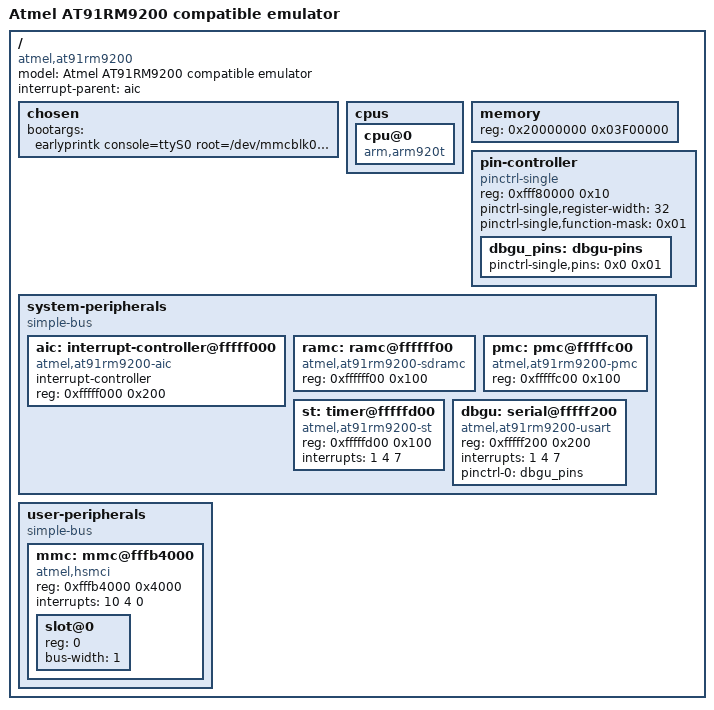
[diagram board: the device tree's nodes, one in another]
/dts-v1/;
/include/ "../ksource/arch/arm/boot/dts/skeleton.dtsi"

/ {
	
	model = "Atmel AT91RM9200 compatible emulator";
	compatible = "atmel,at91rm9200";
	interrupt-parent = <&aic>;

	chosen {
		bootargs = "earlyprintk console=ttyS0 root=/dev/mmcblk0 rootfstype=ext4 rootwait";
	};

	cpus {
		cpu@0 {
			compatible = "arm,arm920t";
		};
	};

	memory {
		reg = <0x20000000 0x03F00000>;
	};

	pin-controller {

		compatible = "pinctrl-single";
		reg = <0xfff80000 0x10>;
		pinctrl-single,register-width = <32>;
		pinctrl-single,function-mask = <0x01>;

		dbgu_pins: dbgu-pins {
			pinctrl-single,pins = <0x0 0x01>;
		};

	};

	system-peripherals {

		compatible = "simple-bus";
		#address-cells = <1>;
		#size-cells = <1>;
		ranges;

		aic: interrupt-controller@fffff000 {
			#interrupt-cells = <3>;
			compatible = "atmel,at91rm9200-aic";
			interrupt-controller;
			reg = <0xfffff000 0x200>;
		};

		ramc: ramc@ffffff00 {
			compatible = "atmel,at91rm9200-sdramc";
			reg = <0xffffff00 0x100>;
		};

		pmc: pmc@fffffc00 {
			compatible = "atmel,at91rm9200-pmc";
			reg = <0xfffffc00 0x100>;
		};

		st: timer@fffffd00 {
			compatible = "atmel,at91rm9200-st";
			reg = <0xfffffd00 0x100>;
			interrupts = <1 4 7>;
		};

		dbgu: serial@fffff200 {
			compatible = "atmel,at91rm9200-usart";
			reg = <0xfffff200 0x200>;
			interrupts = <1 4 7>;
			pinctrl-names = "default";
			pinctrl-0 = <&dbgu_pins>;
		};

	};

	user-peripherals {

		compatible = "simple-bus";
		#address-cells = <1>;
		#size-cells = <1>;
		ranges;

		mmc: mmc@fffb4000 {
			compatible = "atmel,hsmci";
			reg = <0xfffb4000 0x4000>;
			interrupts = <10 4 0>;
			#address-cells = <1>;
			#size-cells = <0>;
			slot@0 {
				reg = <0>;
				bus-width = <1>;
			};
		};

	};
};
